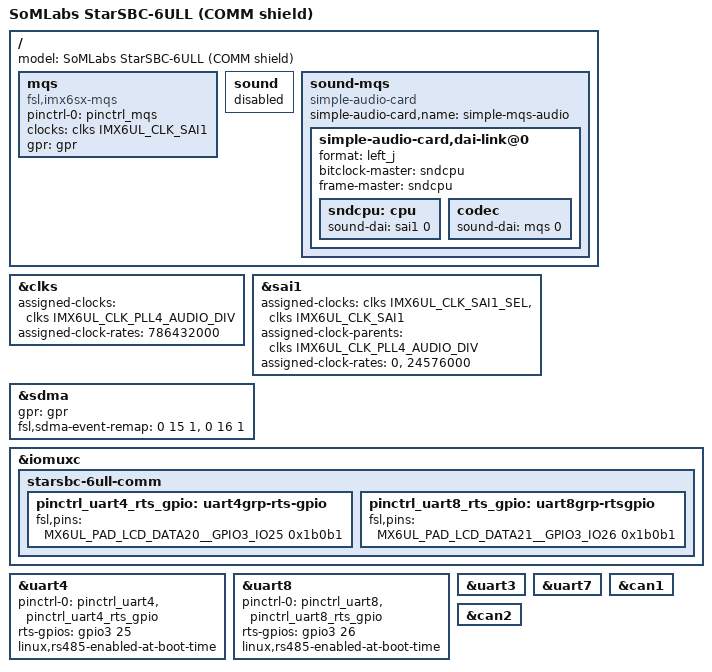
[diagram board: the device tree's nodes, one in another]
// SPDX-License-Identifier: GPL-2.0-or-later
/*
 * Copyright (C) 2021 SoMLabs
 */

#include "starsbc-6ull.dts"

/ {
	model = "SoMLabs StarSBC-6ULL (COMM shield)";

	mqs: mqs {
		#sound-dai-cells = <0>;
		compatible = "fsl,imx6sx-mqs";
		pinctrl-names = "default";
		pinctrl-0 = <&pinctrl_mqs>;
		clocks = <&clks IMX6UL_CLK_SAI1>;
		clock-names = "mclk";
		gpr = <&gpr>;
		status = "okay";
	};

	sound {
		status = "disabled";
	};

	sound-mqs {
		compatible = "simple-audio-card";
		simple-audio-card,name = "simple-mqs-audio";

		simple-audio-card,dai-link@0 {
			format = "left_j";
			bitclock-master = <&sndcpu>;
			frame-master = <&sndcpu>;

			sndcpu: cpu {
				sound-dai = <&sai1 0>;
			};
			codec {
				sound-dai = <&mqs 0>;
			};
		};
	};
};

&clks {
	assigned-clocks = <&clks IMX6UL_CLK_PLL4_AUDIO_DIV>;
	assigned-clock-rates = <786432000>;
};

&sai1 {
	assigned-clocks = <&clks IMX6UL_CLK_SAI1_SEL>, <&clks IMX6UL_CLK_SAI1>;
	assigned-clock-parents = <&clks IMX6UL_CLK_PLL4_AUDIO_DIV>;
	assigned-clock-rates = <0>, <24576000>;
	status = "okay";
};

&sdma {
	gpr = <&gpr>;
	fsl,sdma-event-remap = <0 15 1>, <0 16 1>;
};

&iomuxc {

	starsbc-6ull-comm {
		/* pinmux settings for COMM shield */

		pinctrl_uart4_rts_gpio: uart4grp-rts-gpio {
			fsl,pins = <
				MX6UL_PAD_LCD_DATA20__GPIO3_IO25		0x1b0b1
			>;
		};

		pinctrl_uart8_rts_gpio: uart8grp-rtsgpio {
			fsl,pins = <
				MX6UL_PAD_LCD_DATA21__GPIO3_IO26		0x1b0b1
			>;
		};

	};
};

&uart4 {	/* RS485 */
	pinctrl-names = "default";
	pinctrl-0 = <&pinctrl_uart4 &pinctrl_uart4_rts_gpio>;
	/delete-property/ uart-has-rtscts;
	rts-gpios = <&gpio3 25 GPIO_ACTIVE_HIGH>;
	linux,rs485-enabled-at-boot-time;
	status = "okay";
};

&uart8 {	/* RS485 */
	pinctrl-names = "default";
	pinctrl-0 = <&pinctrl_uart8 &pinctrl_uart8_rts_gpio>;
	/delete-property/ uart-has-rtscts;
	rts-gpios = <&gpio3 26 GPIO_ACTIVE_HIGH>;
	linux,rs485-enabled-at-boot-time;
	status = "okay";
};

&uart3 {	/* RS232 */
	status = "okay";
};

&uart7 {	/* RS232 */
	status = "okay";
};

&can1 {
	status = "okay";
};

&can2 {
	status = "okay";
};
